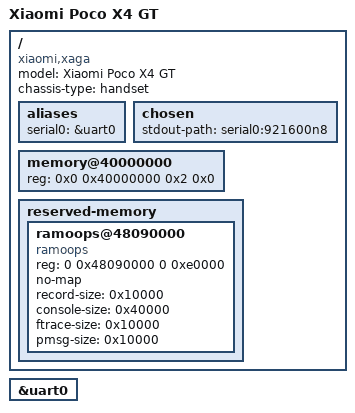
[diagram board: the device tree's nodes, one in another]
// SPDX-License-Identifier: (GPL-2.0 OR MIT)

/dts-v1/;
#include "mt6895.dtsi"

/ {
	model = "Xiaomi Poco X4 GT";
	compatible = "xiaomi,xaga", "mediatek,mt6895";
	chassis-type = "handset";

	aliases {
		serial0 = &uart0;
	};

	chosen {
		stdout-path = "serial0:921600n8";
	};

	memory@40000000 {
		device_type = "memory";
		/* The size is updated by the bootloader. */
		reg = <0x0 0x40000000 0x2 0x0>;
	};

	reserved-memory {
		#address-cells = <2>;
		#size-cells = <2>;
		ranges;

		/* The firmware carveouts are added by the bootloader. */

		ramoops@48090000 {
			compatible = "ramoops";
			reg = <0 0x48090000 0 0xe0000>;
			no-map;
			record-size = <0x10000>;
			console-size = <0x40000>;
			ftrace-size = <0x10000>;
			pmsg-size = <0x10000>;
		};
	};
};

&uart0 {
	status = "okay";
};
